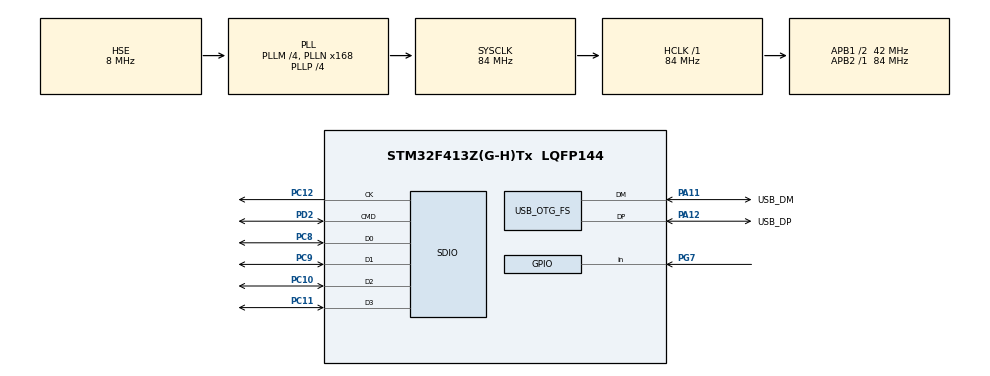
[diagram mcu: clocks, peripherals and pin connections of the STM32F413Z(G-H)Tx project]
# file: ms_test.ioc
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FATFS.BSP.number=1
FATFS0.BSP.STBoard=false
FATFS0.BSP.api=Unknown
FATFS0.BSP.i2caddr=0
FATFS0.BSP.instance=PG7
FATFS0.BSP.ip=GPIO
FATFS0.BSP.mode=Input
FATFS0.BSP.name=Detect_SDIO
FATFS0.BSP.solution=PG7
Mcu.Family=STM32F4
Mcu.Name=STM32F413Z(G-H)Tx
Mcu.Package=LQFP144
NVIC.OTG_FS_IRQn=true\:0\:0\:false\:false\:true\:false\:true
NVIC.PriorityGroup=NVIC_PRIORITYGROUP_4
PA11.GPIO_Label=USB_DM
PA11.Mode=Device_Only
PA11.Signal=USB_OTG_FS_DM
PA12.GPIO_Label=USB_DP
PA12.Mode=Device_Only
PA12.Signal=USB_OTG_FS_DP
PC10.Mode=SD_4_bits_Wide_bus
PC10.Signal=SDIO_D2
PC11.Mode=SD_4_bits_Wide_bus
PC11.Signal=SDIO_D3
PC12.Mode=SD_4_bits_Wide_bus
PC12.Signal=SDIO_CK
PC8.Mode=SD_4_bits_Wide_bus
PC8.Signal=SDIO_D0
PC9.Mode=SD_4_bits_Wide_bus
PC9.Signal=SDIO_D1
PD2.Mode=SD_4_bits_Wide_bus
PD2.Signal=SDIO_CMD
PG7.GPIO_PuPd=GPIO_PULLUP
PG7.Signal=GPIO_Input
PH0\ -\ OSC_IN.Mode=HSE-External-Oscillator
PH0\ -\ OSC_IN.Signal=RCC_OSC_IN
PH1\ -\ OSC_OUT.Mode=HSE-External-Oscillator
PH1\ -\ OSC_OUT.Signal=RCC_OSC_OUT
ProjectManager.HeapSize=0x2000
ProjectManager.StackSize=0x400
ProjectManager.TargetToolchain=STM32CubeIDE
RCC.48MHZClocksFreq_Value=24000000
RCC.AHBFreq_Value=84000000
RCC.APB1CLKDivider=RCC_HCLK_DIV2
RCC.APB1Freq_Value=42000000
RCC.APB1TimFreq_Value=84000000
RCC.APB2Freq_Value=84000000
RCC.APB2TimFreq_Value=84000000
RCC.CortexFreq_Value=84000000
RCC.HCLKFreq_Value=84000000
RCC.HSE_VALUE=8000000
RCC.HSI_VALUE=16000000
RCC.PLLM=4
RCC.PLLMUL=RCC_PLL_MUL9
RCC.PLLN=168
RCC.PLLP=RCC_PLLP_DIV4
RCC.PLLQ=7
RCC.PLLSourceVirtual=RCC_PLLSOURCE_HSE
RCC.PRESCALERUSB=RCC_USBCLKSOURCE_PLL_DIV1_5
RCC.SYSCLKFreq_VALUE=84000000
RCC.SYSCLKSource=RCC_SYSCLKSOURCE_PLLCLK
RCC.SYSCLKSourceVirtual=RCC_SYSCLKSOURCE_PLLCLK
RCC.USBFreq_Value=48000000
RCC.VCOOutputFreq_Value=336000000
SDIO.ClockDiv=3
USB_DEVICE.CLASS_NAME_FS=MSC
USB_DEVICE.VirtualMode=Msc
USB_DEVICE.VirtualModeFS=Msc_FS
USB_OTG_FS.VirtualMode=Device_Only
VP_FATFS_VS_SDIO.Mode=SDIO
VP_USB_DEVICE_VS_USB_DEVICE_MSC_FS.Mode=MSC_FS
board=NUCLEO-F413ZH

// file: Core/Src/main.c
/* USER CODE BEGIN Header */
/**
  ******************************************************************************
  * @file           : main.c
  * @brief          : Main program body
  ******************************************************************************
  * @attention
  *
  * <h2><center>&copy; Copyright (c) 2020 STMicroelectronics.
  * All rights reserved.</center></h2>
  *
  * This software component is licensed by ST under BSD 3-Clause license,
  * the "License"; You may not use this file except in compliance with the
  * License. You may obtain a copy of the License at:
  *                        opensource.org/licenses/BSD-3-Clause
  *
  ******************************************************************************
  */
/* USER CODE END Header */

#include "main.h"
#include "fatfs.h"
#include "usb_device.h"

SD_HandleTypeDef hsd;

void SystemClock_Config(void);
static void MX_GPIO_Init(void);
static void MX_SDIO_SD_Init(void);

int main(void)
{

  /* MCU Configuration--------------------------------------------------------*/

  /* Reset of all peripherals, Initializes the Flash interface and the Systick. */
  HAL_Init();

  /* Configure the system clock */
  SystemClock_Config();

  /* Initialize all configured peripherals */
  MX_GPIO_Init();
  MX_SDIO_SD_Init();
  MX_USB_DEVICE_Init();
  MX_FATFS_Init();
  /* USER CODE BEGIN 2 */
 // char *Buffer_Block_Tx;
  //Buffer_Block_Tx = '123';
  /* USER CODE END 2 */

  /* Infinite loop */
  while (1)
  {

  }
}

void SystemClock_Config(void)
{
  RCC_OscInitTypeDef RCC_OscInitStruct = {0};
  RCC_ClkInitTypeDef RCC_ClkInitStruct = {0};
  RCC_PeriphCLKInitTypeDef PeriphClkInitStruct = {0};

  /** Configure the main internal regulator output voltage
  */
  __HAL_RCC_PWR_CLK_ENABLE();
  __HAL_PWR_VOLTAGESCALING_CONFIG(PWR_REGULATOR_VOLTAGE_SCALE1);
  /** Initializes the CPU, AHB and APB busses clocks
  */
  RCC_OscInitStruct.OscillatorType = RCC_OSCILLATORTYPE_HSE;
  RCC_OscInitStruct.HSEState = RCC_HSE_ON;
  RCC_OscInitStruct.PLL.PLLState = RCC_PLL_ON;
  RCC_OscInitStruct.PLL.PLLSource = RCC_PLLSOURCE_HSE;
  RCC_OscInitStruct.PLL.PLLM = 4;
  RCC_OscInitStruct.PLL.PLLN = 168;
  RCC_OscInitStruct.PLL.PLLP = RCC_PLLP_DIV4;
  RCC_OscInitStruct.PLL.PLLQ = 7;
  RCC_OscInitStruct.PLL.PLLR = 2;
  if (HAL_RCC_OscConfig(&RCC_OscInitStruct) != HAL_OK)
  {
    Error_Handler();
  }
  /** Initializes the CPU, AHB and APB busses clocks
  */
  RCC_ClkInitStruct.ClockType = RCC_CLOCKTYPE_HCLK|RCC_CLOCKTYPE_SYSCLK
                              |RCC_CLOCKTYPE_PCLK1|RCC_CLOCKTYPE_PCLK2;
  RCC_ClkInitStruct.SYSCLKSource = RCC_SYSCLKSOURCE_PLLCLK;
  RCC_ClkInitStruct.AHBCLKDivider = RCC_SYSCLK_DIV1;
  RCC_ClkInitStruct.APB1CLKDivider = RCC_HCLK_DIV2;
  RCC_ClkInitStruct.APB2CLKDivider = RCC_HCLK_DIV1;

  if (HAL_RCC_ClockConfig(&RCC_ClkInitStruct, FLASH_LATENCY_3) != HAL_OK)
  {
    Error_Handler();
  }
  PeriphClkInitStruct.PeriphClockSelection = RCC_PERIPHCLK_SDIO|RCC_PERIPHCLK_CLK48;
  PeriphClkInitStruct.Clk48ClockSelection = RCC_CLK48CLKSOURCE_PLLQ;
  PeriphClkInitStruct.SdioClockSelection = RCC_SDIOCLKSOURCE_CLK48;
  if (HAL_RCCEx_PeriphCLKConfig(&PeriphClkInitStruct) != HAL_OK)
  {
    Error_Handler();
  }
}

static void MX_SDIO_SD_Init(void)
{

  hsd.Instance = SDIO;
  hsd.Init.ClockEdge = SDIO_CLOCK_EDGE_RISING;
  hsd.Init.ClockBypass = SDIO_CLOCK_BYPASS_DISABLE;
  hsd.Init.ClockPowerSave = SDIO_CLOCK_POWER_SAVE_DISABLE;
  hsd.Init.BusWide = SDIO_BUS_WIDE_1B;
  hsd.Init.HardwareFlowControl = SDIO_HARDWARE_FLOW_CONTROL_DISABLE;
  hsd.Init.ClockDiv = 3;
  /* USER CODE BEGIN SDIO_Init 2 */
  HAL_SD_Init(&hsd);
  HAL_SD_InitCard(&hsd);
  /* USER CODE END SDIO_Init 2 */

}

static void MX_GPIO_Init(void)
{
  GPIO_InitTypeDef GPIO_InitStruct = {0};

  /* GPIO Ports Clock Enable */
  __HAL_RCC_GPIOH_CLK_ENABLE();
  __HAL_RCC_GPIOG_CLK_ENABLE();
  __HAL_RCC_GPIOC_CLK_ENABLE();
  __HAL_RCC_GPIOA_CLK_ENABLE();
  __HAL_RCC_GPIOD_CLK_ENABLE();

  /*Configure GPIO pin : PG7 */
  GPIO_InitStruct.Pin = GPIO_PIN_7;
  GPIO_InitStruct.Mode = GPIO_MODE_INPUT;
  GPIO_InitStruct.Pull = GPIO_PULLUP;
  HAL_GPIO_Init(GPIOG, &GPIO_InitStruct);

}

void Error_Handler(void)
{
}

/************************ (C) COPYRIGHT STMicroelectronics *****END OF FILE****/
